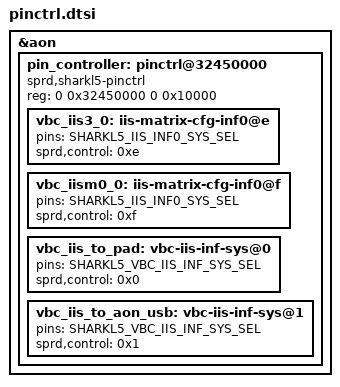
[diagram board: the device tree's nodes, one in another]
// SPDX-License-Identifier: GPL-2.0-only
/*
 * Unisoc UMS312 Pinctrl DTS file
 *
 * Copyright (C) 2022, Unisoc Inc.
 */

&aon {
	pin_controller: pinctrl@32450000 {
		compatible = "sprd,sharkl5-pinctrl";
		reg = <0 0x32450000 0 0x10000>;

		vbc_iis3_0: iis-matrix-cfg-inf0@e {
			pins = "SHARKL5_IIS_INF0_SYS_SEL";
			sprd,control = <0xe>;
		};

		vbc_iism0_0: iis-matrix-cfg-inf0@f {
			pins = "SHARKL5_IIS_INF0_SYS_SEL";
			sprd,control = <0xf>;
		};

		vbc_iis_to_pad: vbc-iis-inf-sys@0 {
			pins = "SHARKL5_VBC_IIS_INF_SYS_SEL";
			sprd,control = <0x0>;
		};

		vbc_iis_to_aon_usb: vbc-iis-inf-sys@1 {
			pins = "SHARKL5_VBC_IIS_INF_SYS_SEL";
			sprd,control = <0x1>;
		};
	};
};
